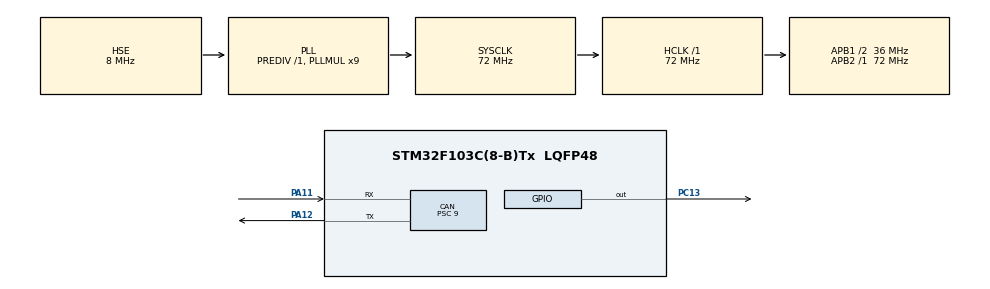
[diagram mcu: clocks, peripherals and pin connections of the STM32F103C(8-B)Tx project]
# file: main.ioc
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CAN.BS1=CAN_BS1_3TQ
CAN.BS2=CAN_BS2_4TQ
CAN.CalculateTimeBit=2000
CAN.CalculateTimeQuantum=250.0
CAN.Prescaler=9
CAN.SJW=CAN_SJW_1TQ
Mcu.Family=STM32F1
Mcu.Name=STM32F103C(8-B)Tx
Mcu.Package=LQFP48
NVIC.PriorityGroup=NVIC_PRIORITYGROUP_4
NVIC.USB_LP_CAN1_RX0_IRQn=true\:0\:0\:false\:false\:true\:true\:true
PA11.Mode=Master
PA11.Signal=CAN_RX
PA12.Mode=Master
PA12.Signal=CAN_TX
PA13.Mode=Serial_Wire
PA13.Signal=SYS_JTMS-SWDIO
PA14.Mode=Serial_Wire
PA14.Signal=SYS_JTCK-SWCLK
PC13-TAMPER-RTC.Signal=GPIO_Output
PD0-OSC_IN.Mode=HSE-External-Oscillator
PD0-OSC_IN.Signal=RCC_OSC_IN
PD1-OSC_OUT.Mode=HSE-External-Oscillator
PD1-OSC_OUT.Signal=RCC_OSC_OUT
ProjectManager.HeapSize=0x200
ProjectManager.StackSize=0x400
ProjectManager.TargetToolchain=Makefile
RCC.ADCPresc=RCC_ADCPCLK2_DIV6
RCC.AHBFreq_Value=72000000
RCC.APB1CLKDivider=RCC_HCLK_DIV2
RCC.APB1Freq_Value=36000000
RCC.APB1TimFreq_Value=72000000
RCC.APB2Freq_Value=72000000
RCC.APB2TimFreq_Value=72000000
RCC.EnbaleCSS=true
RCC.HCLKFreq_Value=72000000
RCC.PLLMUL=RCC_PLL_MUL9
RCC.PLLSourceVirtual=RCC_PLLSOURCE_HSE
RCC.SYSCLKFreq_VALUE=72000000
RCC.SYSCLKSource=RCC_SYSCLKSOURCE_PLLCLK
RCC.USBFreq_Value=72000000
board=custom

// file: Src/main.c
/* USER CODE BEGIN Header */
/**
  ******************************************************************************
  * @file           : main.c
  * @brief          : Main program body
  ******************************************************************************
  * @attention
  *
  * <h2><center>&copy; Copyright (c) 2020 STMicroelectronics.
  * All rights reserved.</center></h2>
  *
  * This software component is licensed by ST under BSD 3-Clause license,
  * the "License"; You may not use this file except in compliance with the
  * License. You may obtain a copy of the License at:
  *                        opensource.org/licenses/BSD-3-Clause
  *
  ******************************************************************************
  */
/* USER CODE END Header */
#include "main.h"
#include "can.h"
#include "gpio.h"

void SystemClock_Config(void);

/* USER CODE BEGIN 0 */
CAN_RxHeaderTypeDef rxHeader;                //CAN Bus Transmit Header
CAN_TxHeaderTypeDef txHeader;                //CAN Bus Receive Header
uint8_t canRX[8] = {0, 0, 0, 0, 0, 0, 0, 0}; //CAN Bus Receive Buffer
CAN_FilterTypeDef canfil;                    //CAN Bus Filter
uint32_t canMailbox;                         //CAN Bus Mail box variable
void HAL_CAN_RxFifo0MsgPendingCallback(CAN_HandleTypeDef *hcan1)
{
  HAL_CAN_GetRxMessage(hcan1, CAN_RX_FIFO0, &rxHeader, canRX); //Receive CAN bus message to canRX buffer
  HAL_GPIO_TogglePin(GPIOC, GPIO_PIN_13);                      // toggle PA3 LED
}
/* USER CODE END 0 */

int main(void)
{

  /* MCU Configuration--------------------------------------------------------*/

  /* Reset of all peripherals, Initializes the Flash interface and the Systick. */
  HAL_Init();

  /* Configure the system clock */
  SystemClock_Config();

  /* Initialize all configured peripherals */
  MX_GPIO_Init();
  MX_CAN_Init();

  /* Infinite loop */
  /* USER CODE BEGIN WHILE */

  canfil.FilterBank = 0;
  canfil.FilterMode = CAN_FILTERMODE_IDMASK;
  canfil.FilterFIFOAssignment = CAN_RX_FIFO0;
  canfil.FilterIdHigh = 0;
  canfil.FilterIdLow = 0;
  canfil.FilterMaskIdHigh = 0;
  canfil.FilterMaskIdLow = 0;
  canfil.FilterScale = CAN_FILTERSCALE_32BIT;
  canfil.FilterActivation = ENABLE;
  canfil.SlaveStartFilterBank = 14;

  txHeader.DLC = 8; // Number of bites to be transmitted max- 8
  txHeader.IDE = CAN_ID_STD;
  txHeader.RTR = CAN_RTR_DATA;
  txHeader.StdId = 0x030;
  txHeader.ExtId = 0x02;
  txHeader.TransmitGlobalTime = DISABLE;

  HAL_CAN_ConfigFilter(&hcan, &canfil);                             //Initialize CAN Filter
  HAL_CAN_Start(&hcan);                                             //Initialize CAN Bus
  HAL_CAN_ActivateNotification(&hcan, CAN_IT_RX_FIFO0_MSG_PENDING); // Initi

  while (1)
  {

    /*uint8_t csend[] = {0x08, 0x07, 0x06, 0x05, 0x04, 0x03, 0x02, 0x01};
    HAL_GPIO_WritePin(GPIOC, GPIO_PIN_13, 1);
    if (HAL_CAN_AddTxMessage(&hcan, &txHeader, csend, &canMailbox) != HAL_OK)
    {
      Error_Handler();
    }*/
    /*HAL_Delay(300);
    HAL_GPIO_WritePin(GPIOC, GPIO_PIN_13, 0);
    HAL_Delay(1000);*/
  }
  /* USER CODE END WHILE */

}

void SystemClock_Config(void)
{
  RCC_OscInitTypeDef RCC_OscInitStruct = {0};
  RCC_ClkInitTypeDef RCC_ClkInitStruct = {0};

  /** Initializes the RCC Oscillators according to the specified parameters
  * in the RCC_OscInitTypeDef structure.
  */
  RCC_OscInitStruct.OscillatorType = RCC_OSCILLATORTYPE_HSE;
  RCC_OscInitStruct.HSEState = RCC_HSE_ON;
  RCC_OscInitStruct.HSEPredivValue = RCC_HSE_PREDIV_DIV1;
  RCC_OscInitStruct.HSIState = RCC_HSI_ON;
  RCC_OscInitStruct.PLL.PLLState = RCC_PLL_ON;
  RCC_OscInitStruct.PLL.PLLSource = RCC_PLLSOURCE_HSE;
  RCC_OscInitStruct.PLL.PLLMUL = RCC_PLL_MUL9;
  if (HAL_RCC_OscConfig(&RCC_OscInitStruct) != HAL_OK)
  {
    Error_Handler();
  }
  /** Initializes the CPU, AHB and APB buses clocks
  */
  RCC_ClkInitStruct.ClockType = RCC_CLOCKTYPE_HCLK | RCC_CLOCKTYPE_SYSCLK | RCC_CLOCKTYPE_PCLK1 | RCC_CLOCKTYPE_PCLK2;
  RCC_ClkInitStruct.SYSCLKSource = RCC_SYSCLKSOURCE_PLLCLK;
  RCC_ClkInitStruct.AHBCLKDivider = RCC_SYSCLK_DIV1;
  RCC_ClkInitStruct.APB1CLKDivider = RCC_HCLK_DIV2;
  RCC_ClkInitStruct.APB2CLKDivider = RCC_HCLK_DIV1;

  if (HAL_RCC_ClockConfig(&RCC_ClkInitStruct, FLASH_LATENCY_2) != HAL_OK)
  {
    Error_Handler();
  }
  /** Enables the Clock Security System
  */
  HAL_RCC_EnableCSS();
}

void Error_Handler(void)
{
}

/************************ (C) COPYRIGHT STMicroelectronics *****END OF FILE****/
